# S6E2C5xL register map
Vendor: Cypress; File version: 2.1
CPU: CM4 r0p1, little endian, MPU, FPU, 4 interrupt priority bits
Registers are 32-bit, read-write, reset 0x0 unless marked. A register's access mark holds for its fields unless they carry their own. Offsets are from the block's base; [hi:lo] are bit positions; {n}, {i} and the like mark numbered series.

## GPIO
Base 0x4006F000
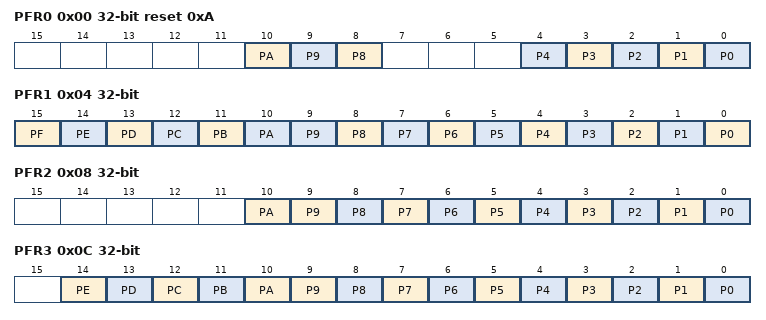
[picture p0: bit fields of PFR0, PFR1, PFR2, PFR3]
0x00 PFR0 reset 0xA — Port Function Setting Register 0 [BHW]
  [10] PA — Bit10 of PFR0
  [9] P9 — Bit9 of PFR0
  [8] P8 — Bit8 of PFR0
  [n] P{n} (n=0..4) — Bit{n} of PFR0
0x04 PFR1 — Port Function Setting Register 1 [BHW]
  [15] PF — Bit15 of PFR1
  [14] PE — Bit14 of PFR1
  [13] PD — Bit13 of PFR1
  [12] PC — Bit12 of PFR1
  [11] PB — Bit11 of PFR1
  [10] PA — Bit10 of PFR1
  [n] P{n} (n=0..9) — Bit{n} of PFR1
0x08 PFR2 — Port Function Setting Register 2 [BHW]
  [10] PA — Bit10 of PFR2
  [n] P{n} (n=0..9) — Bit{n} of PFR2
0x0C PFR3 — Port Function Setting Register 3 [BHW]
  [14] PE — Bit14 of PFR3
  [13] PD — Bit13 of PFR3
  [12] PC — Bit12 of PFR3
  [11] PB — Bit11 of PFR3
  [10] PA — Bit10 of PFR3
  [n] P{n} (n=0..9) — Bit{n} of PFR3
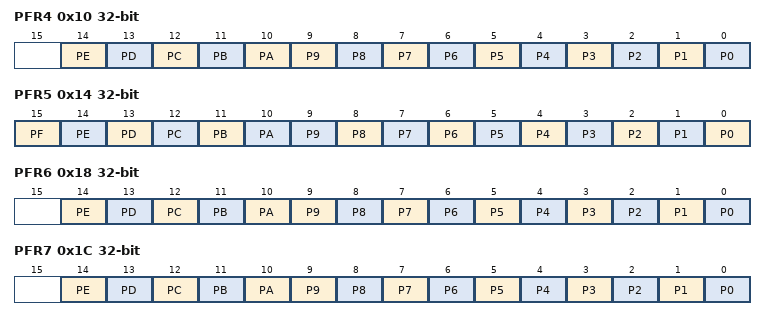
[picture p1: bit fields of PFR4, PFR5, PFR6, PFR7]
0x10 PFR4 — Port Function Setting Register 4 [BHW]
  [14] PE — Bit14 of PFR4
  [13] PD — Bit13 of PFR4
  [12] PC — Bit12 of PFR4
  [11] PB — Bit11 of PFR4
  [10] PA — Bit10 of PFR4
  [n] P{n} (n=0..9) — Bit{n} of PFR4
0x14 PFR5 — Port Function Setting Register 5 [BHW]
  [15] PF — Bit15 of PFR5
  [14] PE — Bit14 of PFR5
  [13] PD — Bit13 of PFR5
  [12] PC — Bit12 of PFR5
  [11] PB — Bit11 of PFR5
  [10] PA — Bit10 of PFR5
  [n] P{n} (n=0..9) — Bit{n} of PFR5
0x18 PFR6 — Port Function Setting Register 6 [BHW]
  [14] PE — Bit14 of PFR6
  [13] PD — Bit13 of PFR6
  [12] PC — Bit12 of PFR6
  [11] PB — Bit11 of PFR6
  [10] PA — Bit10 of PFR6
  [n] P{n} (n=0..9) — Bit{n} of PFR6
0x1C PFR7 — Port Function Setting Register 7 [BHW]
  [14] PE — Bit14 of PFR7
  [13] PD — Bit13 of PFR7
  [12] PC — Bit12 of PFR7
  [11] PB — Bit11 of PFR7
  [10] PA — Bit10 of PFR7
  [n] P{n} (n=0..9) — Bit{n} of PFR7
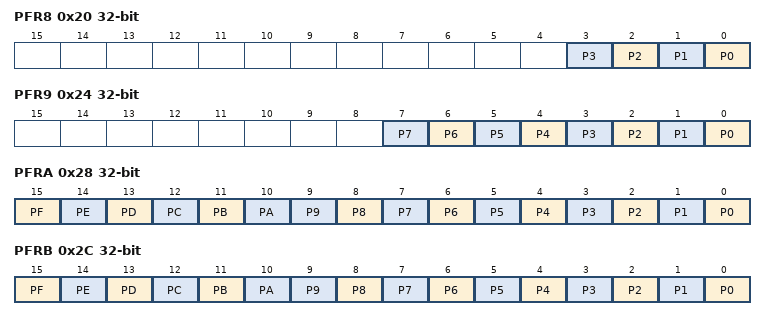
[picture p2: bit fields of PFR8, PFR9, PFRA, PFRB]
0x20 PFR8 — Port Function Setting Register 8 [BHW]
  [n] P{n} (n=0..3) — Bit{n} of PFR8
0x24 PFR9 — Port Function Setting Register 9 [BHW]
  [n] P{n} (n=0..7) — Bit{n} of PFR9
0x28 PFRA — Port Function Setting Register A [BHW]
  [15] PF — Bit15 of PFRA
  [14] PE — Bit14 of PFRA
  [13] PD — Bit13 of PFRA
  [12] PC — Bit12 of PFRA
  [11] PB — Bit11 of PFRA
  [10] PA — Bit10 of PFRA
  [n] P{n} (n=0..9) — Bit{n} of PFRA
0x2C PFRB — Port Function Setting Register B [BHW]
  [15] PF — Bit15 of PFRB
  [14] PE — Bit14 of PFRB
  [13] PD — Bit13 of PFRB
  [12] PC — Bit12 of PFRB
  [11] PB — Bit11 of PFRB
  [10] PA — Bit10 of PFRB
  [n] P{n} (n=0..9) — Bit{n} of PFRB
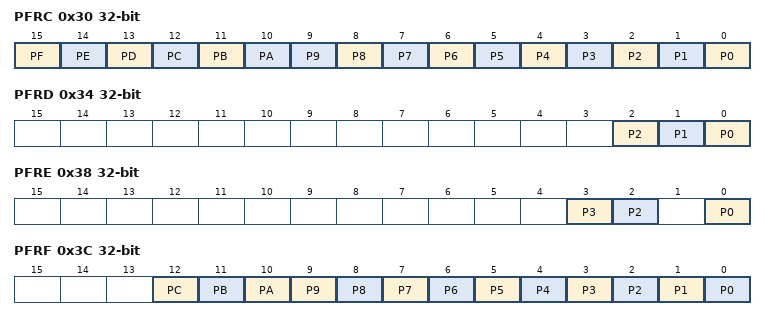
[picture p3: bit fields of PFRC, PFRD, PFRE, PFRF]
0x30 PFRC — Port Function Setting Register C [BHW]
  [15] PF — Bit15 of PFRC
  [14] PE — Bit14 of PFRC
  [13] PD — Bit13 of PFRC
  [12] PC — Bit12 of PFRC
  [11] PB — Bit11 of PFRC
  [10] PA — Bit10 of PFRC
  [n] P{n} (n=0..9) — Bit{n} of PFRC
0x34 PFRD — Port Function Setting Register D [BHW]
  [2] P2 — Bit2 of PFRD
  [1] P1 — Bit1 of PFRD
  [0] P0 — Bit0 of PFRD
0x38 PFRE — Port Function Setting Register E [BHW]
  [3] P3 — Bit3 of PFRE
  [2] P2 — Bit2 of PFRE
  [0] P0 — Bit0 of PFRE
0x3C PFRF — Port Function Setting Register F [BHW]
  [12] PC — Bit12 of PFRF
  [11] PB — Bit11 of PFRF
  [10] PA — Bit10 of PFRF
  [n] P{n} (n=0..9) — Bit{n} of PFRF
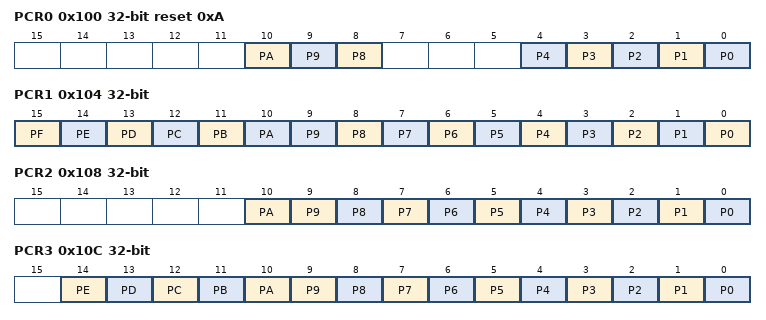
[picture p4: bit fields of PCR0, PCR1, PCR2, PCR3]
0x100 PCR0 reset 0xA — Pull-up Setting Register 0 [BHW]
  [10] PA — Bit10 of PCR0
  [9] P9 — Bit9 of PCR0
  [8] P8 — Bit8 of PCR0
  [n] P{n} (n=0..4) — Bit{n} of PCR0
0x104 PCR1 — Pull-up Setting Register 1 [BHW]
  [15] PF — Bit15 of PCR1
  [14] PE — Bit14 of PCR1
  [13] PD — Bit13 of PCR1
  [12] PC — Bit12 of PCR1
  [11] PB — Bit11 of PCR1
  [10] PA — Bit10 of PCR1
  [n] P{n} (n=0..9) — Bit{n} of PCR1
0x108 PCR2 — Pull-up Setting Register 2 [BHW]
  [10] PA — Bit10 of PCR2
  [n] P{n} (n=0..9) — Bit{n} of PCR2
0x10C PCR3 — Pull-up Setting Register 3 [BHW]
  [14] PE — Bit14 of PCR3
  [13] PD — Bit13 of PCR3
  [12] PC — Bit12 of PCR3
  [11] PB — Bit11 of PCR3
  [10] PA — Bit10 of PCR3
  [n] P{n} (n=0..9) — Bit{n} of PCR3
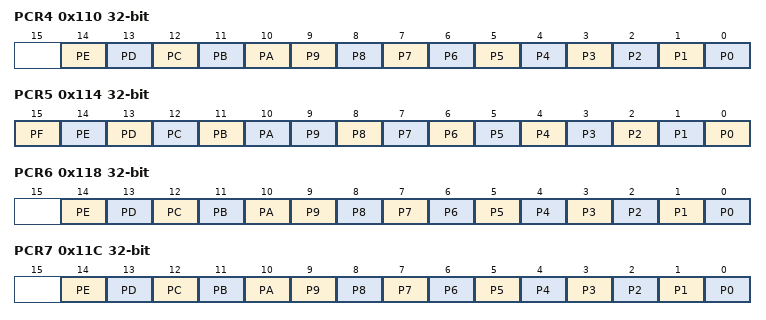
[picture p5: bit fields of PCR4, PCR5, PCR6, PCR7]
0x110 PCR4 — Pull-up Setting Register 4 [BHW]
  [14] PE — Bit14 of PCR4
  [13] PD — Bit13 of PCR4
  [12] PC — Bit12 of PCR4
  [11] PB — Bit11 of PCR4
  [10] PA — Bit10 of PCR4
  [n] P{n} (n=0..9) — Bit{n} of PCR4
0x114 PCR5 — Pull-up Setting Register 5 [BHW]
  [15] PF — Bit15 of PCR5
  [14] PE — Bit14 of PCR5
  [13] PD — Bit13 of PCR5
  [12] PC — Bit12 of PCR5
  [11] PB — Bit11 of PCR5
  [10] PA — Bit10 of PCR5
  [n] P{n} (n=0..9) — Bit{n} of PCR5
0x118 PCR6 — Pull-up Setting Register 6 [BHW]
  [14] PE — Bit14 of PCR6
  [13] PD — Bit13 of PCR6
  [12] PC — Bit12 of PCR6
  [11] PB — Bit11 of PCR6
  [10] PA — Bit10 of PCR6
  [n] P{n} (n=0..9) — Bit{n} of PCR6
0x11C PCR7 — Pull-up Setting Register 7 [BHW]
  [14] PE — Bit14 of PCR7
  [13] PD — Bit13 of PCR7
  [12] PC — Bit12 of PCR7
  [11] PB — Bit11 of PCR7
  [10] PA — Bit10 of PCR7
  [n] P{n} (n=0..9) — Bit{n} of PCR7
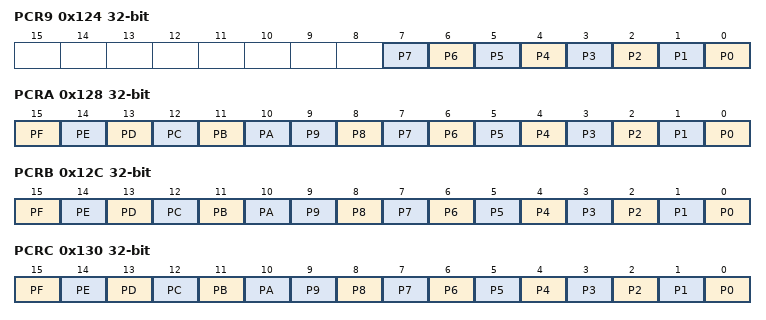
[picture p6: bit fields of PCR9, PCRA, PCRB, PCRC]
0x124 PCR9 — Pull-up Setting Register 9 [BHW]
  [n] P{n} (n=0..7) — Bit{n} of PCR9
0x128 PCRA — Pull-up Setting Register A [BHW]
  [15] PF — Bit15 of PCRA
  [14] PE — Bit14 of PCRA
  [13] PD — Bit13 of PCRA
  [12] PC — Bit12 of PCRA
  [11] PB — Bit11 of PCRA
  [10] PA — Bit10 of PCRA
  [n] P{n} (n=0..9) — Bit{n} of PCRA
0x12C PCRB — Pull-up Setting Register B [BHW]
  [15] PF — Bit15 of PCRB
  [14] PE — Bit14 of PCRB
  [13] PD — Bit13 of PCRB
  [12] PC — Bit12 of PCRB
  [11] PB — Bit11 of PCRB
  [10] PA — Bit10 of PCRB
  [n] P{n} (n=0..9) — Bit{n} of PCRB
0x130 PCRC — Pull-up Setting Register C [BHW]
  [15] PF — Bit15 of PCRC
  [14] PE — Bit14 of PCRC
  [13] PD — Bit13 of PCRC
  [12] PC — Bit12 of PCRC
  [11] PB — Bit11 of PCRC
  [10] PA — Bit10 of PCRC
  [n] P{n} (n=0..9) — Bit{n} of PCRC
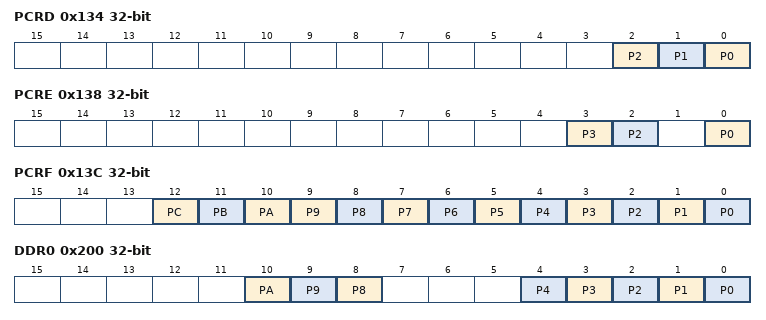
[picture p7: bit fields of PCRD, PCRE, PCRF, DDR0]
0x134 PCRD — Pull-up Setting Register D [BHW]
  [2] P2 — Bit2 of PCRD
  [1] P1 — Bit1 of PCRD
  [0] P0 — Bit0 of PCRD
0x138 PCRE — Pull-up Setting Register E [BHW]
  [3] P3 — Bit3 of PCRE
  [2] P2 — Bit2 of PCRE
  [0] P0 — Bit0 of PCRE
0x13C PCRF — Pull-up Setting Register F [BHW]
  [12] PC — Bit12 of PCRF
  [11] PB — Bit11 of PCRF
  [10] PA — Bit10 of PCRF
  [n] P{n} (n=0..9) — Bit{n} of PCRF
0x200 DDR0 — Port input/output Direction Setting Register 0 [BHW]
  [10] PA — Bit10 of DDR0
  [9] P9 — Bit9 of DDR0
  [8] P8 — Bit8 of DDR0
  [n] P{n} (n=0..4) — Bit{n} of DDR0
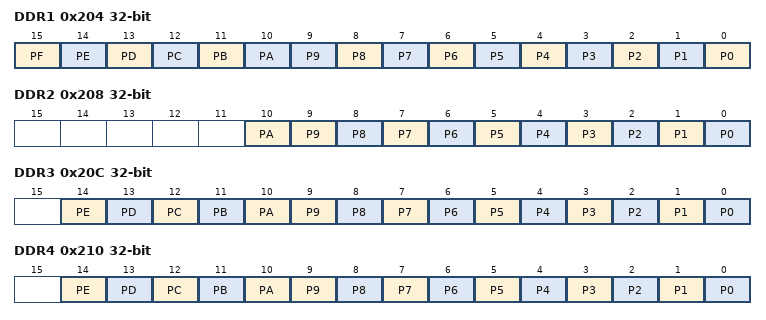
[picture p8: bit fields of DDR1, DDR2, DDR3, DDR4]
0x204 DDR1 — Port input/output Direction Setting Register 1 [BHW]
  [15] PF — Bit15 of DDR1
  [14] PE — Bit14 of DDR1
  [13] PD — Bit13 of DDR1
  [12] PC — Bit12 of DDR1
  [11] PB — Bit11 of DDR1
  [10] PA — Bit10 of DDR1
  [n] P{n} (n=0..9) — Bit{n} of DDR1
0x208 DDR2 — Port input/output Direction Setting Register 2 [BHW]
  [10] PA — Bit10 of DDR2
  [n] P{n} (n=0..9) — Bit{n} of DDR2
0x20C DDR3 — Port input/output Direction Setting Register 3 [BHW]
  [14] PE — Bit14 of DDR3
  [13] PD — Bit13 of DDR3
  [12] PC — Bit12 of DDR3
  [11] PB — Bit11 of DDR3
  [10] PA — Bit10 of DDR3
  [n] P{n} (n=0..9) — Bit{n} of DDR3
0x210 DDR4 — Port input/output Direction Setting Register 4 [BHW]
  [14] PE — Bit14 of DDR4
  [13] PD — Bit13 of DDR4
  [12] PC — Bit12 of DDR4
  [11] PB — Bit11 of DDR4
  [10] PA — Bit10 of DDR4
  [n] P{n} (n=0..9) — Bit{n} of DDR4
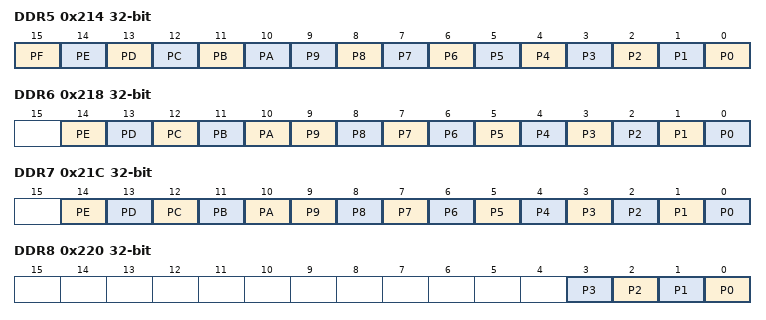
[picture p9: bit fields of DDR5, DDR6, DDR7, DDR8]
0x214 DDR5 — Port input/output Direction Setting Register 5 [BHW]
  [15] PF — Bit15 of DDR5
  [14] PE — Bit14 of DDR5
  [13] PD — Bit13 of DDR5
  [12] PC — Bit12 of DDR5
  [11] PB — Bit11 of DDR5
  [10] PA — Bit10 of DDR5
  [n] P{n} (n=0..9) — Bit{n} of DDR5
0x218 DDR6 — Port input/output Direction Setting Register 6 [BHW]
  [14] PE — Bit14 of DDR6
  [13] PD — Bit13 of DDR6
  [12] PC — Bit12 of DDR6
  [11] PB — Bit11 of DDR6
  [10] PA — Bit10 of DDR6
  [n] P{n} (n=0..9) — Bit{n} of DDR6
0x21C DDR7 — Port input/output Direction Setting Register 7 [BHW]
  [14] PE — Bit14 of DDR7
  [13] PD — Bit13 of DDR7
  [12] PC — Bit12 of DDR7
  [11] PB — Bit11 of DDR7
  [10] PA — Bit10 of DDR7
  [n] P{n} (n=0..9) — Bit{n} of DDR7
0x220 DDR8 — Port input/output Direction Setting Register 8 [BHW]
  [n] P{n} (n=0..3) — Bit{n} of DDR8
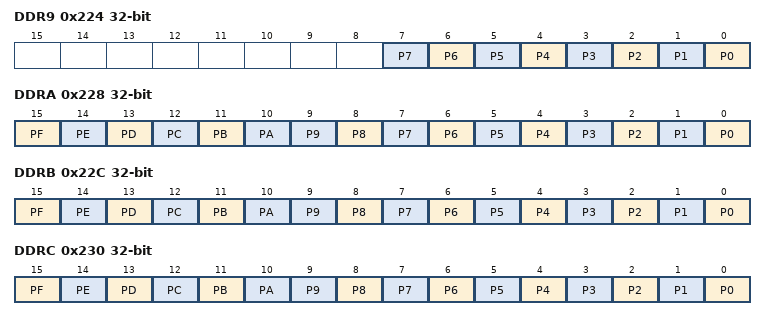
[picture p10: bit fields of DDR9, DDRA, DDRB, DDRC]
0x224 DDR9 — Port input/output Direction Setting Register 9 [BHW]
  [n] P{n} (n=0..7) — Bit{n} of DDR9
0x228 DDRA — Port input/output Direction Setting Register A [BHW]
  [15] PF — Bit15 of DDRA
  [14] PE — Bit14 of DDRA
  [13] PD — Bit13 of DDRA
  [12] PC — Bit12 of DDRA
  [11] PB — Bit11 of DDRA
  [10] PA — Bit10 of DDRA
  [n] P{n} (n=0..9) — Bit{n} of DDRA
0x22C DDRB — Port input/output Direction Setting Register B [BHW]
  [15] PF — Bit15 of DDRB
  [14] PE — Bit14 of DDRB
  [13] PD — Bit13 of DDRB
  [12] PC — Bit12 of DDRB
  [11] PB — Bit11 of DDRB
  [10] PA — Bit10 of DDRB
  [n] P{n} (n=0..9) — Bit{n} of DDRB
0x230 DDRC — Port input/output Direction Setting Register C [BHW]
  [15] PF — Bit15 of DDRC
  [14] PE — Bit14 of DDRC
  [13] PD — Bit13 of DDRC
  [12] PC — Bit12 of DDRC
  [11] PB — Bit11 of DDRC
  [10] PA — Bit10 of DDRC
  [n] P{n} (n=0..9) — Bit{n} of DDRC
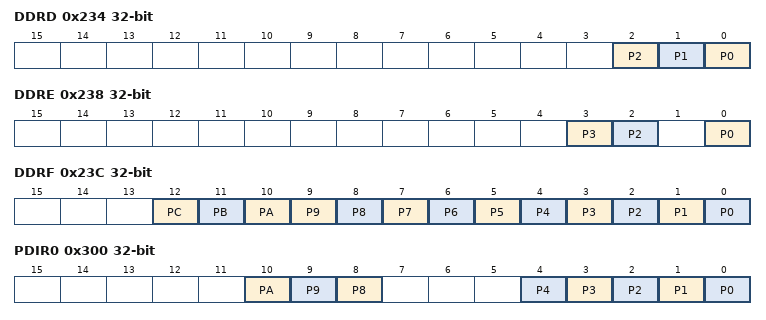
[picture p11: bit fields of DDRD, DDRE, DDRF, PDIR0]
0x234 DDRD — Port input/output Direction Setting Register D [BHW]
  [2] P2 — Bit2 of DDRD
  [1] P1 — Bit1 of DDRD
  [0] P0 — Bit0 of DDRD
0x238 DDRE — Port input/output Direction Setting Register E [BHW]
  [3] P3 — Bit3 of DDRE
  [2] P2 — Bit2 of DDRE
  [0] P0 — Bit0 of DDRE
0x23C DDRF — Port input/output Direction Setting Register F [BHW]
  [12] PC — Bit12 of DDRF
  [11] PB — Bit11 of DDRF
  [10] PA — Bit10 of DDRF
  [n] P{n} (n=0..9) — Bit{n} of DDRF
0x300 PDIR0 ro — Port Input Data Register 0 [BHW]
  [10] PA rw — Bit10 of PDIR0
  [9] P9 rw — Bit9 of PDIR0
  [8] P8 rw — Bit8 of PDIR0
  [n] P{n} rw (n=0..4) — Bit{n} of PDIR0
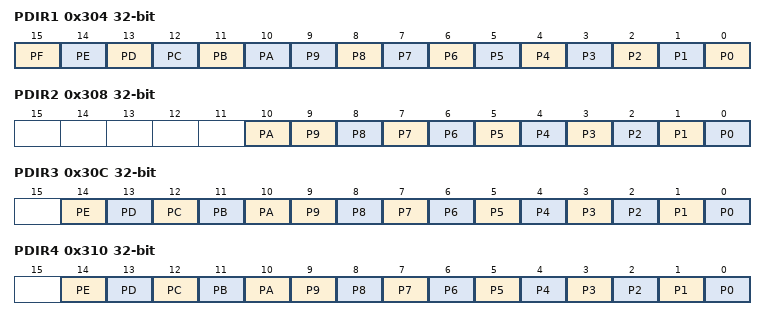
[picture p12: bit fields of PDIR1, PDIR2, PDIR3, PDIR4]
0x304 PDIR1 ro — Port Input Data Register 1 [BHW]
  [15] PF rw — Bit15 of PDIR1
  [14] PE rw — Bit14 of PDIR1
  [13] PD rw — Bit13 of PDIR1
  [12] PC rw — Bit12 of PDIR1
  [11] PB rw — Bit11 of PDIR1
  [10] PA rw — Bit10 of PDIR1
  [n] P{n} rw (n=0..9) — Bit{n} of PDIR1
0x308 PDIR2 ro — Port Input Data Register 2 [BHW]
  [10] PA rw — Bit10 of PDIR2
  [n] P{n} rw (n=0..9) — Bit{n} of PDIR2
0x30C PDIR3 ro — Port Input Data Register 3 [BHW]
  [14] PE rw — Bit14 of PDIR3
  [13] PD rw — Bit13 of PDIR3
  [12] PC rw — Bit12 of PDIR3
  [11] PB rw — Bit11 of PDIR3
  [10] PA rw — Bit10 of PDIR3
  [n] P{n} rw (n=0..9) — Bit{n} of PDIR3
0x310 PDIR4 ro — Port Input Data Register 4 [BHW]
  [14] PE rw — Bit14 of PDIR4
  [13] PD rw — Bit13 of PDIR4
  [12] PC rw — Bit12 of PDIR4
  [11] PB rw — Bit11 of PDIR4
  [10] PA rw — Bit10 of PDIR4
  [n] P{n} rw (n=0..9) — Bit{n} of PDIR4
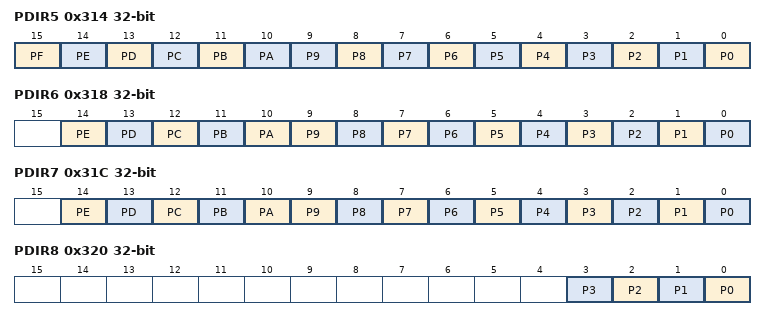
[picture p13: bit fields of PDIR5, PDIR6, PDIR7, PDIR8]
0x314 PDIR5 ro — Port Input Data Register 5 [BHW]
  [15] PF rw — Bit15 of PDIR5
  [14] PE rw — Bit14 of PDIR5
  [13] PD rw — Bit13 of PDIR5
  [12] PC rw — Bit12 of PDIR5
  [11] PB rw — Bit11 of PDIR5
  [10] PA rw — Bit10 of PDIR5
  [n] P{n} rw (n=0..9) — Bit{n} of PDIR5
0x318 PDIR6 ro — Port Input Data Register 6 [BHW]
  [14] PE rw — Bit14 of PDIR6
  [13] PD rw — Bit13 of PDIR6
  [12] PC rw — Bit12 of PDIR6
  [11] PB rw — Bit11 of PDIR6
  [10] PA rw — Bit10 of PDIR6
  [n] P{n} rw (n=0..9) — Bit{n} of PDIR6
0x31C PDIR7 ro — Port Input Data Register 7 [BHW]
  [14] PE rw — Bit14 of PDIR7
  [13] PD rw — Bit13 of PDIR7
  [12] PC rw — Bit12 of PDIR7
  [11] PB rw — Bit11 of PDIR7
  [10] PA rw — Bit10 of PDIR7
  [n] P{n} rw (n=0..9) — Bit{n} of PDIR7
0x320 PDIR8 ro — Port Input Data Register 8 [BHW]
  [n] P{n} rw (n=0..3) — Bit{n} of PDIR8
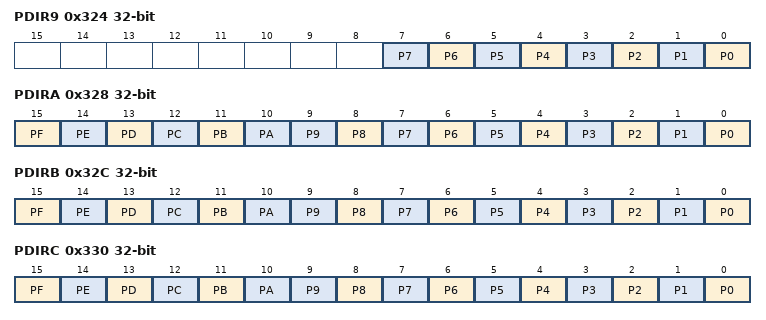
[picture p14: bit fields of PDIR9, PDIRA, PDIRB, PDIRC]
0x324 PDIR9 ro — Port Input Data Register 9 [BHW]
  [n] P{n} rw (n=0..7) — Bit{n} of PDIR9
0x328 PDIRA ro — Port Input Data Register A [BHW]
  [15] PF rw — Bit15 of PDIRA
  [14] PE rw — Bit14 of PDIRA
  [13] PD rw — Bit13 of PDIRA
  [12] PC rw — Bit12 of PDIRA
  [11] PB rw — Bit11 of PDIRA
  [10] PA rw — Bit10 of PDIRA
  [n] P{n} rw (n=0..9) — Bit{n} of PDIRA
0x32C PDIRB ro — Port Input Data Register B [BHW]
  [15] PF rw — Bit15 of PDIRB
  [14] PE rw — Bit14 of PDIRB
  [13] PD rw — Bit13 of PDIRB
  [12] PC rw — Bit12 of PDIRB
  [11] PB rw — Bit11 of PDIRB
  [10] PA rw — Bit10 of PDIRB
  [n] P{n} rw (n=0..9) — Bit{n} of PDIRB
0x330 PDIRC ro — Port Input Data Register C [BHW]
  [15] PF rw — Bit15 of PDIRC
  [14] PE rw — Bit14 of PDIRC
  [13] PD rw — Bit13 of PDIRC
  [12] PC rw — Bit12 of PDIRC
  [11] PB rw — Bit11 of PDIRC
  [10] PA rw — Bit10 of PDIRC
  [n] P{n} rw (n=0..9) — Bit{n} of PDIRC
0x334 PDIRD ro — Port Input Data Register D [BHW]
  [2] P2 rw — Bit2 of PDIRD
  [1] P1 rw — Bit1 of PDIRD
  [0] P0 rw — Bit0 of PDIRD
0x338 PDIRE ro — Port Input Data Register E [BHW]
  [3] P3 rw — Bit3 of PDIRE
  [2] P2 rw — Bit2 of PDIRE
  [0] P0 rw — Bit0 of PDIRE
0x33C PDIRF ro — Port Input Data Register F [BHW]
  [12] PC rw — Bit12 of PDIRF
  [11] PB rw — Bit11 of PDIRF
  [10] PA rw — Bit10 of PDIRF
  [n] P{n} rw (n=0..9) — Bit{n} of PDIRF
0x400 PDOR0 — Port Output Data Register 0 [BHW]
  [10] PA — Bit10 of PDOR0
  [9] P9 — Bit9 of PDOR0
  [8] P8 — Bit8 of PDOR0
  [n] P{n} (n=0..4) — Bit{n} of PDOR0
0x404 PDOR1 — Port Output Data Register 1 [BHW]
  [15] PF — Bit15 of PDOR1
  [14] PE — Bit14 of PDOR1
  [13] PD — Bit13 of PDOR1
  [12] PC — Bit12 of PDOR1
  [11] PB — Bit11 of PDOR1
  [10] PA — Bit10 of PDOR1
  [n] P{n} (n=0..9) — Bit{n} of PDOR1
0x408 PDOR2 — Port Output Data Register 2 [BHW]
  [10] PA — Bit10 of PDOR2
  [n] P{n} (n=0..9) — Bit{n} of PDOR2
0x40C PDOR3 — Port Output Data Register 3 [BHW]
  [14] PE — Bit14 of PDOR3
  [13] PD — Bit13 of PDOR3
  [12] PC — Bit12 of PDOR3
  [11] PB — Bit11 of PDOR3
  [10] PA — Bit10 of PDOR3
  [n] P{n} (n=0..9) — Bit{n} of PDOR3
0x410 PDOR4 — Port Output Data Register 4 [BHW]
  [14] PE — Bit14 of PDOR4
  [13] PD — Bit13 of PDOR4
  [12] PC — Bit12 of PDOR4
  [11] PB — Bit11 of PDOR4
  [10] PA — Bit10 of PDOR4
  [n] P{n} (n=0..9) — Bit{n} of PDOR4
0x414 PDOR5 — Port Output Data Register 5 [BHW]
  [15] PF — Bit15 of PDOR5
  [14] PE — Bit14 of PDOR5
  [13] PD — Bit13 of PDOR5
  [12] PC — Bit12 of PDOR5
  [11] PB — Bit11 of PDOR5
  [10] PA — Bit10 of PDOR5
  [n] P{n} (n=0..9) — Bit{n} of PDOR5
0x418 PDOR6 — Port Output Data Register 6 [BHW]
  [14] PE — Bit14 of PDOR6
  [13] PD — Bit13 of PDOR6
  [12] PC — Bit12 of PDOR6
  [11] PB — Bit11 of PDOR6
  [10] PA — Bit10 of PDOR6
  [n] P{n} (n=0..9) — Bit{n} of PDOR6
0x41C PDOR7 — Port Output Data Register 7 [BHW]
  [14] PE — Bit14 of PDOR7
  [13] PD — Bit13 of PDOR7
  [12] PC — Bit12 of PDOR7
  [11] PB — Bit11 of PDOR7
  [10] PA — Bit10 of PDOR7
  [n] P{n} (n=0..9) — Bit{n} of PDOR7
0x420 PDOR8 — Port Output Data Register 8 [BHW]
  [n] P{n} (n=0..3) — Bit{n} of PDOR8
0x424 PDOR9 — Port Output Data Register 9 [BHW]
  [n] P{n} (n=0..7) — Bit{n} of PDOR9
0x428 PDORA — Port Output Data Register A [BHW]
  [15] PF — Bit15 of PDORA
  [14] PE — Bit14 of PDORA
  [13] PD — Bit13 of PDORA
  [12] PC — Bit12 of PDORA
  [11] PB — Bit11 of PDORA
  [10] PA — Bit10 of PDORA
  [n] P{n} (n=0..9) — Bit{n} of PDORA
0x42C PDORB — Port Output Data Register B [BHW]
  [15] PF — Bit15 of PDORB
  [14] PE — Bit14 of PDORB
  [13] PD — Bit13 of PDORB
  [12] PC — Bit12 of PDORB
  [11] PB — Bit11 of PDORB
  [10] PA — Bit10 of PDORB
  [n] P{n} (n=0..9) — Bit{n} of PDORB
0x430 PDORC — Port Output Data Register C [BHW]
  [15] PF — Bit15 of PDORC
  [14] PE — Bit14 of PDORC
  [13] PD — Bit13 of PDORC
  [12] PC — Bit12 of PDORC
  [11] PB — Bit11 of PDORC
  [10] PA — Bit10 of PDORC
  [n] P{n} (n=0..9) — Bit{n} of PDORC
0x434 PDORD — Port Output Data Register D [BHW]
  [2] P2 — Bit2 of PDORD
  [1] P1 — Bit1 of PDORD
  [0] P0 — Bit0 of PDORD
0x438 PDORE — Port Output Data Register E [BHW]
  [3] P3 — Bit3 of PDORE
  [2] P2 — Bit2 of PDORE
  [0] P0 — Bit0 of PDORE
0x43C PDORF — Port Output Data Register F [BHW]
  [12] PC — Bit12 of PDORF
  [11] PB — Bit11 of PDORF
  [10] PA — Bit10 of PDORF
  [n] P{n} (n=0..9) — Bit{n} of PDORF
0x500 ADE reset 0xFFFFFFFF — Analog Input Setting Register [BHW]
  [31] AN31 — Analog Input Ch.31 Setting Register
  [30] AN30 — Analog Input Ch.30 Setting Register
  [29] AN29 — Analog Input Ch.29 Setting Register
  [28] AN28 — Analog Input Ch.28 Setting Register
  [27] AN27 — Analog Input Ch.27 Setting Register
  [26] AN26 — Analog Input Ch.26 Setting Register
  [25] AN25 — Analog Input Ch.25 Setting Register
  [24] AN24 — Analog Input Ch.24 Setting Register
  [23] AN23 — Analog Input Ch.23 Setting Register
  [22] AN22 — Analog Input Ch.22 Setting Register
  [21] AN21 — Analog Input Ch.21 Setting Register
  [20] AN20 — Analog Input Ch.20 Setting Register
  [19] AN19 — Analog Input Ch.19 Setting Register
  [18] AN18 — Analog Input Ch.18 Setting Register
  [17] AN17 — Analog Input Ch.17 Setting Register
  [16] AN16 — Analog Input Ch.16 Setting Register
  [15] AN15 — Analog Input Ch.15 Setting Register
  [14] AN14 — Analog Input Ch.14 Setting Register
  [13] AN13 — Analog Input Ch.13 Setting Register
  [12] AN12 — Analog Input Ch.12 Setting Register
  [11] AN11 — Analog Input Ch.11 Setting Register
  [10] AN10 — Analog Input Ch.10 Setting Register
  [9] AN09 — Analog Input Ch.9 Setting Register
  [8] AN08 — Analog Input Ch.8 Setting Register
  [7] AN07 — Analog Input Ch.7 Setting Register
  [6] AN06 — Analog Input Ch.6 Setting Register
  [5] AN05 — Analog Input Ch.5 Setting Register
  [4] AN04 — Analog Input Ch.4 Setting Register
  [3] AN03 — Analog Input Ch.3 Setting Register
  [2] AN02 — Analog Input Ch.2 Setting Register
  [1] AN01 — Analog Input Ch.1 Setting Register
  [0] AN00 — Analog Input Ch.0 Setting Register
0x580 SPSR reset 0x4 — Special Port Setting Register [BHW]
  [5] USB1C — USB (ch.1) Pin Setting bit
  [4] USB0C — USB (ch.0) Pin Setting bit
  [3:2] MAINXC — Main Clock (Oscillation) Pin Setting bits
0x600 EPFR00 reset 0x30000 — Extended Pin Function Setting Register 00 [BHW]
  [n+24] TRC{n}E (n=0..3) — TRACED Function Select bit {n}
  [17] JTAGEN1S — JTAG Function Select bit 1
  [16] JTAGEN0B — JTAG Function Select bit 0
  [13] USBP1E — USB ch.1 Function Select bit 1
  [9] USBP0E — USB ch.0 Function Select bit 1
  [7:6] SUBOUTE — Sub clock divide output function select bit
  [5:4] RTCCOE — RTC clock output select bit
  [2:1] CROUTE — Internal high-speed CR Oscillation Output Function Select bit
  [0] NMIS — NMIX Function Select bit
0x604 EPFR01 — Extended Pin Function Setting Register 01 [BHW]
  [3n+22:3n+20] IC{n:02}S (n=0..3) — IC{n:02} Input Select bits
  [19:18] FRCK0S — FRCK0 Input Select bits
  [17:16] DTTI0S — DTTIX0 Input Select bits
  [12] DTTI0C — DTTIX0 Function Select bit
  [2n+1:2n] RTO{n:02}E (n=0..5) — RTO{n:02} Output Select bits
0x608 EPFR02 — Extended Pin Function Setting Register 02 [BHW]
  [3n-8:3n-10] IC{n}S (n=10..13) — IC13 Input Select bits
  [19:18] FRCK1S — FRCK1 Input Select bits
  [17:16] DTTI1S — DTTIX1 Input Select bits
  [12] DTTI1C — DTTIX1 Function Select bit
  [2n-19:2n-20] RTO{n}E (n=10..15) — RTO{n} Output Select bits
0x60C EPFR03 — Extended Pin Function Setting Register 03 [BHW]
  [3n-38:3n-40] IC{n}S (n=20..23) — IC23 Input Select bits
  [19:18] FRCK2S — FRCK2 Input Select bits
  [17:16] DTTI2S — DTTIX2 Input Select bits
  [12] DTTI2C — DTTIX2 Function Select bit
  [2n-39:2n-40] RTO{n}E (n=20..25) — RTO{n} Output Select bits
0x610 EPFR04 — Extended Pin Function Setting Register 04 [BHW]
  [29:28] TIOB3S — TIOB3 Input Select bits
  [8n+3:8n+2] TIOA{n}E (n=0..3) — TIOA{n} Output Select bits
  [25:24] TIOA3S — TIOA3 Input Select bits
  [21:20] TIOB2S — TIOB2 Input Select bits
  [13:12] TIOB1S — TIOB1 Input Select bits
  [9:8] TIOA1S — TIOA1 Input Select bits
  [6:4] TIOB0S — TIOB0 Input Select bits
0x614 EPFR05 — Extended Pin Function Setting Register 05 [BHW]
  [8n-27:8n-28] TIOB{n}S (n=4..7) — TIOB{n} Input Select bits
  [8n-29:8n-30] TIOA{n}E (n=4..7) — TIOA{n} Output Select bits
  [25:24] TIOA7S — TIOA7 Input Select bits
  [9:8] TIOA5S — TIOA5 Input Select bits
0x618 EPFR06 — Extended Pin Function Setting Register 06 [BHW]
  [2n+1:2n] EINT{n:02}S (n=0..15) — External Interrupt {n:02} Input Select bits
0x61C EPFR07 — Extended Pin Function Setting Register 07 [BHW]
  [6n+9:6n+8] SCK{n}B (n=0..3) — SCK{n} Input/Output Select bits
  [6n+7:6n+6] SOT{n}B (n=0..3) — SOT{n} Input/Output Select bits
  [6n+5:6n+4] SIN{n}S (n=0..3) — SIN{n} Input Select bits
0x620 EPFR08 — Extended Pin Function Setting Register 08 [BHW]
  [31:30] CTS5S — CTS5 Input/Output Select bits
  [29:28] RTS5E — RTS5 Input/Output Select bits
  [6n-15:6n-16] SCK{n}B (n=4..7) — SCK{n} Input/Output Select bits
  [6n-17:6n-18] SOT{n}B (n=4..7) — SOT{n} Input/Output Select bits
  [6n-19:6n-20] SIN{n}S (n=4..7) — SIN{n} Input Select bits
  [3:2] CTS4S — CTS4 Input/Output Select bits
  [1:0] RTS4E — RTS4 Input/Output Select bits
0x624 EPFR09 — Extended Pin Function Setting Register 09 [BHW]
  [31:30] CTX1E — CTX1E Output Select bits
  [29:28] CRX1S — CRX1S Input Select bits
  [27:26] CTX0E — CTX0E Output Select bits
  [25:24] CRX0S — CRX0S Input Select bits
  [23:20] ADTRG2S — ADTRG2 Input Select bits
  [19:16] ADTRG1S — ADTRG1 Input Select bits
  [15:12] ADTRG0S — ADTRG0 Input Select bits
  [11:10] QZIN1S — QZIN1S Input Select bits
  [9:8] QBIN1S — QBIN1S Input Select bits
  [7:6] QAIN1S — QAIN1S Input Select bits
  [5:4] QZIN0S — QZIN0S Input Select bits
  [3:2] QBIN0S — QBIN0S Input Select bits
  [1:0] QAIN0S — QAIN0S Input Select bits
0x628 EPFR10 — Extended Pin Function Setting Register 10 [BHW]
  [n+7] UEA{n:02}E (n=8..24) — UEA{n:02}E Output Select bit
  [14] UEAOOE — UEAOOE Output Select bit
  [n+6] UECS{n}E (n=1..7) — UECS{n}E Output Select bit
  [6] UEFLSE — UEFLSE Output Select bit
  [5] UEOEXE — UEOEXE Output Select bit
  [4] UEDQME — UEDQME Output Select bit
  [3] UEWEXE — UEWEXE Output Select bit
  [2] UECLKE — UECLKE Output Select bit
  [1] UEDTHB — UEDTHB Input/Output Select bit
  [0] UEDEFB — UEDEFB Input/Output Select bit
0x62C EPFR11 — Extended Pin Function Setting Register 11 [BHW]
  [25] UERLC — UERLC relocation select bit
  [n+9] UED{n:02}B (n=0..15) — UED{n:02}B Input/Output Select bit
  [n+1] UEA{n:02}E (n=1..7) — UEA{n:02}E Output Select bit
  [1] UECS0E — UECS0E Output Select bit
  [0] UEALEE — UEALEE Output Select bit
0x630 EPFR12 — Extended Pin Function Setting Register 12 [BHW]
  [8n-59:8n-60] TIOB{n}S (n=8..11) — TIOB{n} Input Select bits
  [8n-61:8n-62] TIOA{n}E (n=8..11) — TIOA{n} Output Select bits
  [25:24] TIOA11S — TIOA11 Input Select bits
  [9:8] TIOA9S — TIOA9 Input Select bits
0x634 EPFR13 — Extended Pin Function Setting Register 13 [BHW]
  [8n-91:8n-92] TIOB{n}S (n=12..15) — TIOB{n} Input Select bits
  [8n-93:8n-94] TIOA{n}E (n=12..15) — TIOA{n} Output Select bits
  [25:24] TIOA15S — TIOA15 Input Select bits
  [9:8] TIOA13S — TIOA13 Input Select bits
0x638 EPFR14 — Extended Pin Function Setting Register 14 [BHW]
  [29:28] E_SPLC — Input cutoff Select bit in Standby of input Pin for Ethernet-MAC
  [27] E_PSE — PPS0_PPS1 Output Select bit for Ethernet-MAC
  [26] E_CKE — E_COUT Output Select bit
  [25] E_MD1B — E_MDO1 I/O Select bit
  [24] E_MD0B — E_MDO0 I/O Select bit
  [23] E_MC1B — E_MDC1 I/O Select bit
  [22] E_MC0E — E_MDC0 Output Select bit
  [21] E_TE1E — E_TXER0_TXEN1 Output Select bit
  [20] E_TE0E — E_TXEN0 Output Select bit
  [19] E_TD1E — E_TX02_TX10/E_TX03_TX11 Output Select bit
  [18] E_TD0E — E_TX00/E_TX01 Output Select bit
  [5:4] QZIN2S — QDU-ch.2 ZIN Input Pin bits
  [3:2] QBIN2S — QDU-ch.2 BIN Input Pin bits
  [1:0] QAIN2S — QDU-ch.2 AIN Input Pin bits
0x63C EPFR15 — Extended Pin Function Setting Register 15 [BHW]
  [2n-31:2n-32] EINT{n}S (n=16..31) — External Interrupt {n} Input Select bits
0x640 EPFR16 — Extended Pin Function Setting Register 16 [BHW]
  [29] SFMPBC — MFS ch.B I2C FastMode+ Select bit
  [28] SFMPAC — MFS ch.A I2C FastMode+ Select bit
  [6n-39:6n-40] SCK{n}B (n=8..11) — SCK{n} Input/Output Select bits
  [6n-41:6n-42] SOT{n}B (n=8..11) — SOT{n} Input/Output Select bits
  [6n-43:6n-44] SIN{n}S (n=8..11) — SIN{n} Input Select bits
  [3:2] SCS7B — SCS7 Input/Output Select bits
  [1:0] SCS6B — SCS6 Select bits
0x644 EPFR17 — Extended Pin Function Setting Register 17 [BHW]
  [6n-63:6n-64] SCK{n}B (n=12..15) — SCK{n} Input/Output Select bits
  [6n-65:6n-66] SOT{n}B (n=12..15) — SOT{n} Input/Output Select bits
  [6n-67:6n-68] SIN{n}S (n=12..15) — SIN{n} Input Select bits
0x648 EPFR18 — Extended Pin Function Setting Register 18 [BHW]
  [29:28] SDWPS — S_WP input select bits
  [27:26] SDCDS — S_CD input select bits
  [2n+19:2n+18] SDDATA{n}B (n=0..3) — SDDATA{n} input/output select bits
  [17:16] SDCMDB — S_CMD input/output select bits
  [15:14] SDCLKE — S_CLK output select bits
  [9:8] QZIN3S — QDU-ch3 ZIN input select bits
  [7:6] QBIN3S — QDU-ch3 BIN input select bits
  [5:4] QAIN3S — QDU-ch3 AIN input select bits
0x64C EPFR19 reset not defined — Extended Pin Function Setting Register 19 [BHW]
0x650 EPFR20 — Extended Pin Function Setting Register 20 [BHW]
  [n-7] UED{n}B (n=16..31) — UED{n}B input/output select bit
  [8] UEDTHHB — UEDTHHB input/output select bit
  [7] UEDQM3E — UEDQM3E output select bit
  [6] UEDQM2E — UEDQM2E output select bit
  [5] UECSXE — UECSXE output select bit
  [4] UEDWEXE — UEDWEXE output select bit
  [3] UECASE — UECASE output select bit
  [2] UERASE — UERASE output select bit
  [1] UESMCEE — UESMCEE output select bit
  [0] UESMCKE — UESMCKE output select bit
0x654 EPFR21 reset not defined — Extended Pin Function Setting Register 21 [BHW]
0x658 EPFR22 reset not defined — Extended Pin Function Setting Register 22 [BHW]
0x65C EPFR23 — Extended Pin Function Setting Register 23 [BHW]
  [2n-131:2n-132] SCS{n}E (n=70..73) — SCS{n} Input Select bits
  [2n-119:2n-120] SCS{n}E (n=60..63) — SCS{n} Input Select bits
0x660 EPFR24 — Extended Pin Function Setting Register 24 [BHW]
  [27:26] I2SM4_SDO1E — I2SDO1 Output Select bits
  [25:24] I2SM4_SDI1S — I2SDI1 Input Select bits
  [23:22] I2SM4_WS1B — I2SWS1 Input/Output Select bits
  [21:20] I2SM4_SCK1B — I2SCK1 Input/Output Select bits
  [19:18] I2SM4_MCLK1E — I2SMCLK1 Output Select bits
  [17:16] I2SM4_MCLK1S — I2SMCLK1 Input Select bits
  [11:10] I2SM4_SDO0E — I2SDO0 Output Select bits
  [9:8] I2SM4_SDI0S — I2SDI0 Input Select bits
  [7:6] I2SM4_WS0B — I2SWS0 Input/Output Select bits
  [5:4] I2SM4_SCK0B — I2SCK0 Input/Output Select bits
  [3:2] I2SM4_MCLK0E — I2SMCLK0 Output Select bits
  [1:0] I2SM4_MCLK0S — I2SMCLK0 Input Select bits
0x664 EPFR25 — Extended Pin Function Setting Register 25 [BHW]
  [3:2] MCTX2E — TX2 Output Select bits
  [1:0] MCRX2S — RX2 Input Select bits
0x668 EPFR26 — Extended Pin Function Setting Register 26 [BHW]
  [2n+11:2n+10] Q_IO{n}B (n=0..3) — Q_IO{n} Input Select bits
  [2n+3:2n+2] Q_CS{n}E (n=0..3) — Q_CS{n} Input Select bits
  [1:0] Q_SCKB — Q_SCK Input Select bits
0x700 PZR0 — Port Pseudo Open Drain Setting Register 0 [BHW]
  [10] PA — Bit10 of PZR0
  [9] P9 — Bit9 of PZR0
  [8] P8 — Bit8 of PZR0
  [n] P{n} (n=0..4) — Bit{n} of PZR0
0x704 PZR1 — Port Pseudo Open Drain Setting Register 1 [BHW]
  [15] PF — Bit15 of PZR1
  [14] PE — Bit14 of PZR1
  [13] PD — Bit13 of PZR1
  [12] PC — Bit12 of PZR1
  [11] PB — Bit11 of PZR1
  [10] PA — Bit10 of PZR1
  [n] P{n} (n=0..9) — Bit{n} of PZR1
0x708 PZR2 — Port Pseudo Open Drain Setting Register 2 [BHW]
  [10] PA — Bit10 of PZR2
  [n] P{n} (n=0..9) — Bit{n} of PZR2
0x70C PZR3 — Port Pseudo Open Drain Setting Register 3 [BHW]
  [14] PE — Bit14 of PZR3
  [13] PD — Bit13 of PZR3
  [12] PC — Bit12 of PZR3
  [11] PB — Bit11 of PZR3
  [10] PA — Bit10 of PZR3
  [n] P{n} (n=0..9) — Bit{n} of PZR3
0x710 PZR4 — Port Pseudo Open Drain Setting Register 4 [BHW]
  [14] PE — Bit14 of PZR4
  [13] PD — Bit13 of PZR4
  [12] PC — Bit12 of PZR4
  [11] PB — Bit11 of PZR4
  [10] PA — Bit10 of PZR4
  [n] P{n} (n=0..9) — Bit{n} of PZR4
0x714 PZR5 — Port Pseudo Open Drain Setting Register 5 [BHW]
  [15] PF — Bit15 of PZR5
  [14] PE — Bit14 of PZR5
  [13] PD — Bit13 of PZR5
  [12] PC — Bit12 of PZR5
  [11] PB — Bit11 of PZR5
  [10] PA — Bit10 of PZR5
  [n] P{n} (n=0..9) — Bit{n} of PZR5
0x718 PZR6 — Port Pseudo Open Drain Setting Register 6 [BHW]
  [14] PE — Bit14 of PZR6
  [13] PD — Bit13 of PZR6
  [12] PC — Bit12 of PZR6
  [11] PB — Bit11 of PZR6
  [10] PA — Bit10 of PZR6
  [n] P{n} (n=0..9) — Bit{n} of PZR6
0x71C PZR7 — Port Pseudo Open Drain Setting Register 7 [BHW]
  [14] PE — Bit14 of PZR7
  [13] PD — Bit13 of PZR7
  [12] PC — Bit12 of PZR7
  [11] PB — Bit11 of PZR7
  [10] PA — Bit10 of PZR7
  [n] P{n} (n=0..9) — Bit{n} of PZR7
0x720 PZR8 — Port Pseudo Open Drain Setting Register 8 [BHW]
  [n] P{n} (n=0..3) — Bit{n} of PZR8
0x724 PZR9 — Port Pseudo Open Drain Setting Register 9 [BHW]
  [n] P{n} (n=0..7) — Bit{n} of PZR9
0x728 PZRA — Port Pseudo Open Drain Setting Register A [BHW]
  [15] PF — Bit15 of PZRA
  [14] PE — Bit14 of PZRA
  [13] PD — Bit13 of PZRA
  [12] PC — Bit12 of PZRA
  [11] PB — Bit11 of PZRA
  [10] PA — Bit10 of PZRA
  [n] P{n} (n=0..9) — Bit{n} of PZRA
0x72C PZRB — Port Pseudo Open Drain Setting Register B [BHW]
  [15] PF — Bit15 of PZRB
  [14] PE — Bit14 of PZRB
  [13] PD — Bit13 of PZRB
  [12] PC — Bit12 of PZRB
  [11] PB — Bit11 of PZRB
  [10] PA — Bit10 of PZRB
  [n] P{n} (n=0..9) — Bit{n} of PZRB
0x730 PZRC — Port Pseudo Open Drain Setting Register C [BHW]
  [15] PF — Bit15 of PZRC
  [14] PE — Bit14 of PZRC
  [13] PD — Bit13 of PZRC
  [12] PC — Bit12 of PZRC
  [11] PB — Bit11 of PZRC
  [10] PA — Bit10 of PZRC
  [n] P{n} (n=0..9) — Bit{n} of PZRC
0x734 PZRD — Port Pseudo Open Drain Setting Register D [BHW]
  [2] P2 — Bit2 of PZRD
  [1] P1 — Bit1 of PZRD
  [0] P0 — Bit0 of PZRD
0x738 PZRE — Port Pseudo Open Drain Setting Register E [BHW]
  [3] P3 — Bit3 of PZRE
  [2] P2 — Bit2 of PZRE
  [0] P0 — Bit0 of PZRE
0x73C PZRF — Port Pseudo Open Drain Setting Register F [BHW]
  [12] PC — Bit12 of PZRF
  [11] PB — Bit11 of PZRF
  [10] PA — Bit10 of PZRF
  [n] P{n} (n=0..9) — Bit{n} of PZRF
0x740 PDSR0 — Port Driver capability Select Register 0 [BHW]
  [10] PA — Bit10 of PDSR0
  [9] P9 — Bit9 of PDSR0
  [8] P8 — Bit8 of PDSR0
  [n] P{n} (n=0..4) — Bit{n} of PDSR0
0x744 PDSR1 — Port Driver capability Select Register 1 [BHW]
  [15] PF — Bit15 of PDSR1
  [14] PE — Bit14 of PDSR1
  [13] PD — Bit13 of PDSR1
  [12] PC — Bit12 of PDSR1
  [11] PB — Bit11 of PDSR1
  [10] PA — Bit10 of PDSR1
  [n] P{n} (n=0..9) — Bit{n} of PDSR1
0x748 PDSR2 — Port Driver capability Select Register 2 [BHW]
  [10] PA — Bit10 of PDSR2
  [n] P{n} (n=0..9) — Bit{n} of PDSR2
0x74C PDSR3 — Port Driver capability Select Register 3 [BHW]
  [14] PE — Bit14 of PDSR3
  [13] PD — Bit13 of PDSR3
  [12] PC — Bit12 of PDSR3
  [11] PB — Bit11 of PDSR3
  [10] PA — Bit10 of PDSR3
  [n] P{n} (n=0..9) — Bit{n} of PDSR3
0x750 PDSR4 — Port Driver capability Select Register 4 [BHW]
  [14] PE — Bit14 of PDSR4
  [13] PD — Bit13 of PDSR4
  [12] PC — Bit12 of PDSR4
  [11] PB — Bit11 of PDSR4
  [10] PA — Bit10 of PDSR4
  [n] P{n} (n=0..9) — Bit{n} of PDSR4
0x754 PDSR5 — Port Driver capability Select Register 5 [BHW]
  [15] PF — Bit15 of PDSR5
  [14] PE — Bit14 of PDSR5
  [13] PD — Bit13 of PDSR5
  [12] PC — Bit12 of PDSR5
  [11] PB — Bit11 of PDSR5
  [10] PA — Bit10 of PDSR5
  [n] P{n} (n=0..9) — Bit{n} of PDSR5
0x758 PDSR6 — Port Driver capability Select Register 6 [BHW]
  [14] PE — Bit14 of PDSR6
  [13] PD — Bit13 of PDSR6
  [12] PC — Bit12 of PDSR6
  [11] PB — Bit11 of PDSR6
  [10] PA — Bit10 of PDSR6
  [n] P{n} (n=0..9) — Bit{n} of PDSR6
0x75C PDSR7 — Port Driver capability Select Register 7 [BHW]
  [14] PE — Bit14 of PDSR7
  [13] PD — Bit13 of PDSR7
  [12] PC — Bit12 of PDSR7
  [11] PB — Bit11 of PDSR7
  [10] PA — Bit10 of PDSR7
  [n] P{n} (n=0..9) — Bit{n} of PDSR7
0x760 PDSR8 — Port Driver capability Select Register 8 [BHW]
  [n] P{n} (n=0..3) — Bit{n} of PDSR8
0x764 PDSR9 — Port Driver capability Select Register 9 [BHW]
  [n] P{n} (n=0..7) — Bit{n} of PDSR9
0x768 PDSRA — Port Driver capability Select Register A [BHW]
  [15] PF — Bit15 of PDSRA
  [14] PE — Bit14 of PDSRA
  [13] PD — Bit13 of PDSRA
  [12] PC — Bit12 of PDSRA
  [11] PB — Bit11 of PDSRA
  [10] PA — Bit10 of PDSRA
  [n] P{n} (n=0..9) — Bit{n} of PDSRA
0x76C PDSRB — Port Driver capability Select Register B [BHW]
  [15] PF — Bit15 of PDSRB
  [14] PE — Bit14 of PDSRB
  [13] PD — Bit13 of PDSRB
  [12] PC — Bit12 of PDSRB
  [11] PB — Bit11 of PDSRB
  [10] PA — Bit10 of PDSRB
  [n] P{n} (n=0..9) — Bit{n} of PDSRB
0x770 PDSRC — Port Driver capability Select Register C [BHW]
  [15] PF — Bit15 of PDSRC
  [14] PE — Bit14 of PDSRC
  [13] PD — Bit13 of PDSRC
  [12] PC — Bit12 of PDSRC
  [11] PB — Bit11 of PDSRC
  [10] PA — Bit10 of PDSRC
  [n] P{n} (n=0..9) — Bit{n} of PDSRC
0x774 PDSRD — Port Driver capability Select Register D [BHW]
  [2] P2 — Bit2 of PDSRD
  [1] P1 — Bit1 of PDSRD
  [0] P0 — Bit0 of PDSRD
0x778 PDSRE — Port Driver capability Select Register E [BHW]
  [3] P3 — Bit3 of PDSRE
  [2] P2 — Bit2 of PDSRE
  [0] P0 — Bit0 of PDSRE
0x77C PDSRF — Port Driver capability Select Register F [BHW]
  [12] PC — Bit12 of PDSRF
  [11] PB — Bit11 of PDSRF
  [10] PA — Bit10 of PDSRF
  [n] P{n} (n=0..9) — Bit{n} of PDSRF
